# haltium_application register map
Vendor: Nordic Semiconductor; Series: nRFHaltium; File version: 1
CPU: CM33 r0p4, little endian, MPU, FPU, 3 interrupt priority bits, 480 interrupts
Registers are 32-bit, read-write, reset 0x0 unless marked. A register's access mark holds for its fields unless they carry their own. Offsets are from the block's base; [hi:lo] are bit positions; 'fields as' and 'values as' point back to an identical list.

## GLOBAL_GGENERIC59_NS — GENERIC 0
Base 0xBF001000
Same registers: GLOBAL_GGENERIC55_NS 0x4F8D3000, GLOBAL_GGENERIC56_NS 0x4F8D4000, GLOBAL_GGENERIC57_NS 0x4F8D5000, GLOBAL_GGENERIC58_NS 0x4F8D6000, GENERIC0_S 0x52002000, GENERIC1_S 0x5200B000, GENERIC4_S 0x5200F000, GENERIC5_S 0x5201D000, GENERIC7_S 0x5201F000, GLOBAL_GGENERIC55_S 0x5F8D3000, GLOBAL_GGENERIC56_S 0x5F8D4000, GLOBAL_GGENERIC57_S 0x5F8D5000, GLOBAL_GGENERIC58_S 0x5F8D6000, GLOBAL_GGENERIC59_S 0xBF001000 (alternate view of GLOBAL_GGENERIC59_NS), GLOBAL_GGENERIC60_NS 0xBF003000, GLOBAL_GGENERIC60_S 0xBF003000 (alternate view of GLOBAL_GGENERIC60_NS), GLOBAL_TSGEN_NS 0xBF041000, GLOBAL_ETB_NS 0xBF044000, GLOBAL_ETR_NS 0xBF045000, GENERIC8_S 0xE0042000
0x00 TASKS_GENERICTASK wo — Generic event
  [0] TASKS_GENERICTASK
    1=Trigger task
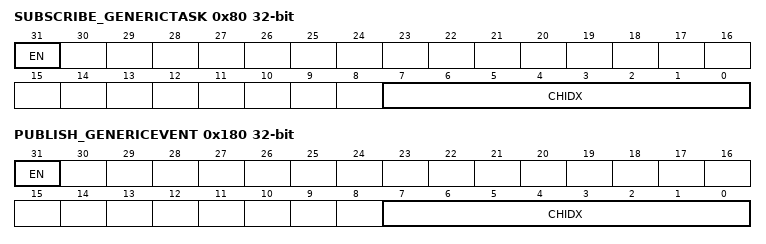
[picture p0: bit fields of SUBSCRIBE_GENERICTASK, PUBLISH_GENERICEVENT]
0x80 SUBSCRIBE_GENERICTASK — Subscribe configuration for task GENERICTASK
  [31] EN
    0=Disabled (Disable subscription); 1=Enabled (Enable subscription)
  [7:0] CHIDX — DPPI channel that task GENERICTASK will subscribe to
0x100 EVENTS_GENERICEVENT — Generic event
  [0] EVENTS_GENERICEVENT
    0=NotGenerated (Event not generated); 1=Generated (Event generated)
0x180 PUBLISH_GENERICEVENT — Publish configuration for event GENERICEVENT
  [31] EN
    0=Disabled (Disable publishing); 1=Enabled (Enable publishing)
  [7:0] CHIDX — DPPI channel that event GENERICEVENT will publish to
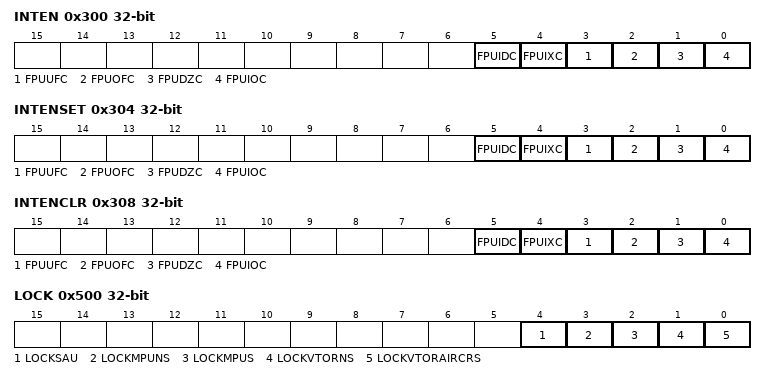
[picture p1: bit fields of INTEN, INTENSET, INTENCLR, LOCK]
0x300 INTEN — Enable or disable interrupt
  [0] GENERICEVENT — Enable or disable interrupt for event GENERICEVENT
    0=Disabled; 1=Enabled
0x304 INTENSET — Enable interrupt
  [0] GENERICEVENT — Write '1' to enable interrupt for event GENERICEVENT
    on read: 0=Disabled (Read: Disabled); 1=Enabled (Read: Enabled) | on write: 1=Set (Enable)
0x308 INTENCLR — Disable interrupt
  [0] GENERICEVENT — Write '1' to disable interrupt for event GENERICEVENT
    on read: 0=Disabled (Read: Disabled); 1=Enabled (Read: Enabled) | on write: 1=Clear (Disable)

## CPUC_S — CM33 SubSystem
Base 0xE0080000
0x100 EVENTS_FPUIOC — An invalid operation exception has occurred in the FPU.
  [0] EVENTS_FPUIOC
    0=NotGenerated (Event not generated); 1=Generated (Event generated)
0x104 EVENTS_FPUDZC — A floating-point divide-by-zero exception has occurred in the FPU.
  [0] EVENTS_FPUDZC
    values as EVENTS_FPUIOC.EVENTS_FPUIOC
0x108 EVENTS_FPUOFC — A floating-point overflow exception has occurred in the FPU.
  [0] EVENTS_FPUOFC
    values as EVENTS_FPUIOC.EVENTS_FPUIOC
0x10C EVENTS_FPUUFC — A floating-point underflow exception has occurred in the FPU.
  [0] EVENTS_FPUUFC
    values as EVENTS_FPUIOC.EVENTS_FPUIOC
0x110 EVENTS_FPUIXC — A floating-point inexact exception has occurred in the FPU.
  [0] EVENTS_FPUIXC
    values as EVENTS_FPUIOC.EVENTS_FPUIOC
0x114 EVENTS_FPUIDC — A floating-point input denormal exception has occurred in the FPU.
  [0] EVENTS_FPUIDC
    values as EVENTS_FPUIOC.EVENTS_FPUIOC
0x300 INTEN — Enable or disable interrupt
  [all] fields
    0=Disabled; 1=Enabled
  [5] FPUIDC — Enable or disable interrupt for event FPUIDC
  [4] FPUIXC — Enable or disable interrupt for event FPUIXC
  [3] FPUUFC — Enable or disable interrupt for event FPUUFC
  [2] FPUOFC — Enable or disable interrupt for event FPUOFC
  [1] FPUDZC — Enable or disable interrupt for event FPUDZC
  [0] FPUIOC — Enable or disable interrupt for event FPUIOC
0x304 INTENSET — Enable interrupt
  [all] fields
    on read: 0=Disabled (Read: Disabled); 1=Enabled (Read: Enabled) | on write: 1=Set (Enable)
  [5] FPUIDC — Write '1' to enable interrupt for event FPUIDC
  [4] FPUIXC — Write '1' to enable interrupt for event FPUIXC
  [3] FPUUFC — Write '1' to enable interrupt for event FPUUFC
  [2] FPUOFC — Write '1' to enable interrupt for event FPUOFC
  [1] FPUDZC — Write '1' to enable interrupt for event FPUDZC
  [0] FPUIOC — Write '1' to enable interrupt for event FPUIOC
0x308 INTENCLR — Disable interrupt
  [all] fields
    on read: 0=Disabled (Read: Disabled); 1=Enabled (Read: Enabled) | on write: 1=Clear (Disable)
  [5] FPUIDC — Write '1' to disable interrupt for event FPUIDC
  [4] FPUIXC — Write '1' to disable interrupt for event FPUIXC
  [3] FPUUFC — Write '1' to disable interrupt for event FPUUFC
  [2] FPUOFC — Write '1' to disable interrupt for event FPUOFC
  [1] FPUDZC — Write '1' to disable interrupt for event FPUDZC
  [0] FPUIOC — Write '1' to disable interrupt for event FPUIOC
0x500 LOCK — Register to lock the certain parts of the CPU from being modified.
  [4] LOCKSAU — Locks the Security Attribution Unit (SAU)
    0=NotLocked (SAU registers can be changed.); 1=Locked (Prevents changes to SAU registers.)
  [3] LOCKMPUNS — Locks the Memory Protection Unit (MPU) for non secure mode.
    0=NotLocked (MPU registers can be changed.); 1=Locked (Prevents changes to MPU registers.)
  [2] LOCKMPUS — Locks the Memory Protection Unit (MPU) for secure mode.
    values as LOCKMPUNS
  [1] LOCKVTORNS — Locks the Vector table Offset Register (VTOR) for non-secure mode.
    0=NotLocked (VTOR can be changed.); 1=Locked (Prevents changes to VTOR.)
  [0] LOCKVTORAIRCRS — Locks both the Vector table Offset Register (VTOR) and Application Interrupt and Reset Control Register (AIRCR) for secure mode.
    0=NotLocked (Both VTOR and AIRCR can be changed.); 1=Locked (Prevents changes to both VTOR and AIRCR.)
0x504 CPUID ro — The identifier for the CPU in this subsystem.
  [31:0] CPUID — The CPU identifier.
